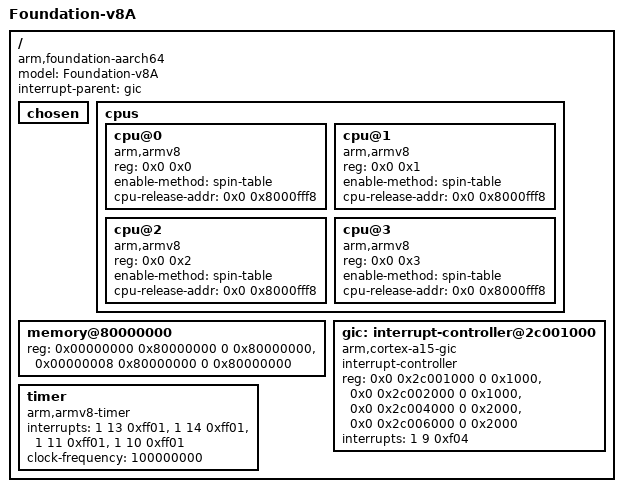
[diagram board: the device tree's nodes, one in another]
/*
 * ARM Ltd.
 *
 * ARMv8 Foundation model DTS
 */

/dts-v1/;

/ {
	model = "Foundation-v8A";
	compatible = "arm,foundation-aarch64", "arm,vexpress";
	interrupt-parent = <&gic>;
	#address-cells = <2>;
	#size-cells = <2>;

	chosen { };

	cpus {
		#address-cells = <2>;
		#size-cells = <0>;

		cpu@0 {
			device_type = "cpu";
			compatible = "arm,armv8";
			reg = <0x0 0x0>;
			enable-method = "spin-table";
			cpu-release-addr = <0x0 0x8000fff8>;
		};
		cpu@1 {
			device_type = "cpu";
			compatible = "arm,armv8";
			reg = <0x0 0x1>;
			enable-method = "spin-table";
			cpu-release-addr = <0x0 0x8000fff8>;
		};
		cpu@2 {
			device_type = "cpu";
			compatible = "arm,armv8";
			reg = <0x0 0x2>;
			enable-method = "spin-table";
			cpu-release-addr = <0x0 0x8000fff8>;
		};
		cpu@3 {
			device_type = "cpu";
			compatible = "arm,armv8";
			reg = <0x0 0x3>;
			enable-method = "spin-table";
			cpu-release-addr = <0x0 0x8000fff8>;
		};
	};

	memory@80000000 {
		device_type = "memory";
		reg = <0x00000000 0x80000000 0 0x80000000>,
		      <0x00000008 0x80000000 0 0x80000000>;
	};

	gic: interrupt-controller@2c001000 {
		compatible = "arm,cortex-a15-gic", "arm,cortex-a9-gic";
		#interrupt-cells = <3>;
		#address-cells = <0>;
		interrupt-controller;
		reg = <0x0 0x2c001000 0 0x1000>,
		      <0x0 0x2c002000 0 0x1000>,
		      <0x0 0x2c004000 0 0x2000>,
		      <0x0 0x2c006000 0 0x2000>;
		interrupts = <1 9 0xf04>;
	};

	timer {
		compatible = "arm,armv8-timer";
		interrupts = <1 13 0xff01>,
			     <1 14 0xff01>,
			     <1 11 0xff01>,
			     <1 10 0xff01>;
		clock-frequency = <100000000>;
	};
};
